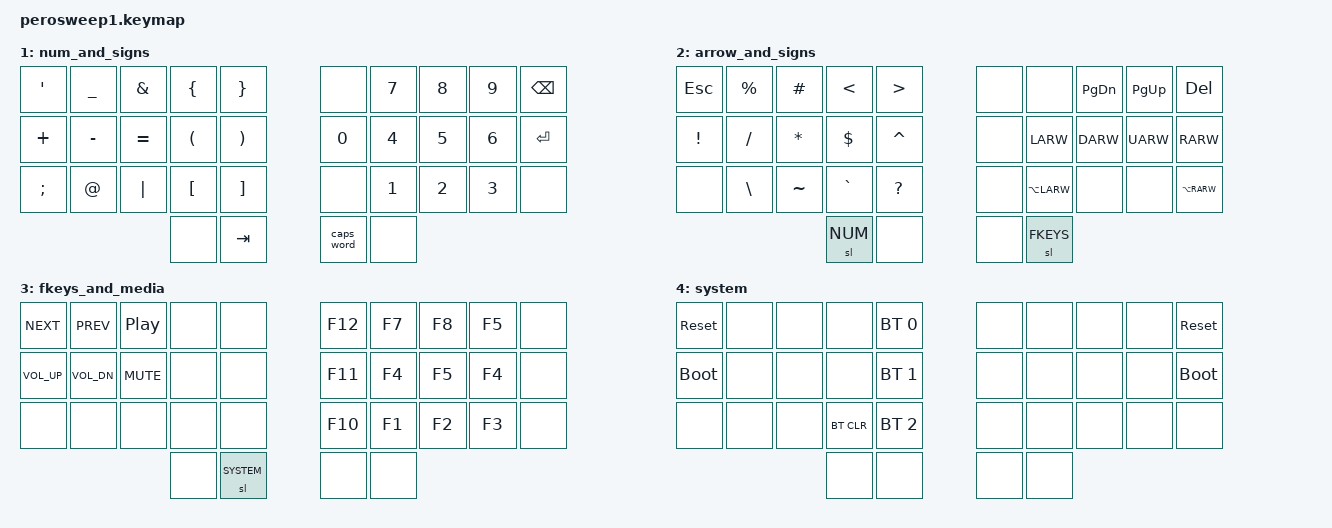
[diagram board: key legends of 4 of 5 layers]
#include <behaviors.dtsi>
#include <dt-bindings/zmk/keys.h>
#include <dt-bindings/zmk/bt.h>

#define ALPHA   0
#define NUM     1
#define ARROW   2
#define FKEYS   3 
#define SYSTEM  4 

// Home row mods macro
#define HRML(k1,k2,k3,k4) &mt LALT k1  &mt LGUI k2  &mt LSHIFT k3  &mt LCTRL k4
#define HRMR(k1,k2,k3,k4) &mt RCTRL k1  &mt RSHIFT k2  &mt RGUI k3  &mt RALT k4

&mt {
    // We use this for the MEH-key only.
    // Higher timeouts are required to prevent misfiring.
    tapping-term-ms = <230>;
    quick_tap_ms = <180>;
    global-quick-tap;
    flavor = "tap-preferred";
};

&sl {
    release-after-ms = <500>;
};

/ {
    behaviors {
        lm: home_row_left {
            compatible = "zmk,behavior-hold-tap";
            label = "home_row_left";
            #binding-cells = <2>;
            tapping-term-ms = <220>;
            quick_tap_ms = <180>;
            flavor = "balanced";
            bindings = <&kp>, <&kp>;
            hold-trigger-key-positions = <5 6 7 8 9 15 16 17 18 19 25 26 27 28 29 32 33>;
        };
        rm: home_row_right {
            compatible = "zmk,behavior-hold-tap";
            label = "home_row_right";
            #binding-cells = <2>;
            tapping-term-ms = <220>;
            quick_tap_ms = <180>;
            flavor = "balanced";
            bindings = <&kp>, <&kp>;
            hold-trigger-key-positions = <0 1 2 3 4 10 11 12 13 14 20 21 22 23 24 30 31>;
        };
    };

    keymap {
        compatible = "zmk,keymap";

        alpha {
        bindings = <

        //╭──────────┬──────────┬──────────┬──────────┬──────────╮   ╭──────────┬──────────┬──────────┬──────────┬──────────╮
        //│  Q       │  W       │  E       │  R       │  T       │   │  Y       │  U       │  I       │  O       │  P       │
            &kp Q      &kp W      &kp E      &kp R      &kp T          &kp Y      &kp U      &kp I      &kp O      &kp P
        //├──────────┼──────────┼──────────┼──────────┼──────────┤   ├──────────┼──────────┼──────────┼──────────┼──────────┤
        //│  A       │  S       │  D       │  F       │  G       │   │  H       │  J       │  K       │  L       │ ' "      │
            HRML(A,        S,         D,         F)     &kp G          &kp H      HRMR(J,        K,         L,        SQT)
        //├──────────┼──────────┼──────────┼──────────┼──────────┤   ├──────────┼──────────┼──────────┼──────────┼──────────┤
        //│  Z       │  X       │  C       │  V       │  B       │   │  N       │  M       │ , <      │ . >      │ / ?      │
            &kp Z      &kp X      &kp C      &kp V      &kp B          &kp N      &kp M      &kp COMMA  &kp DOT    &kp FSLH
        //╰──────────┴──────────┴──────────┼──────────┼──────────┤   ├──────────┼──────────┼──────────┴──────────┴──────────╯
         &sl ARROW  &mt LC(LS(LALT)) SPACE      &sl ARROW  &sl NUM
        >;
        };

        // TODO: We have to wait for `&sl` to time out for `&caps_word` to work.
        num_and_signs {
        bindings = <

        &kp SQT   &kp UNDER  &kp AMPS   &kp LBRC  &kp RBRC     &none   &kp N7  &kp N8  &kp N9  &kp BKSP
        &kp PLUS  &kp MINUS  &kp EQUAL  &kp LPAR  &kp RPAR     &kp N0  &kp N4  &kp N5  &kp N6  &kp ENTER
        &kp SEMI  &kp AT     &kp PIPE   &kp LBKT  &kp RBKT     &none   &kp N1  &kp N2  &kp N3  &none

                                            &none  &kp TAB     &caps_word  &none
        >;
        };

        arrow_and_signs {
        bindings = <

        &kp ESC   &kp PRCNT  &kp HASH   &kp LT     &kp GT       &none      &none         &kp PG_DN  &kp PG_UP  &kp DEL
        &kp EXCL  &kp SLASH  &kp ASTRK  &kp DLLR   &kp CARET    &none      &kp LARW      &kp DARW   &kp UARW   &kp RARW  
        &none     &kp BSLH   &kp TILDE  &kp GRAVE  &kp QMARK    &none      &kp LA(LARW)  &none      &none      &kp LA(RARW)    

                                              &sl NUM  &none    &none      &sl FKEYS
        >;
        };

        // The switch to the SYSTEM layer is put on the second thumb key on purpose
        // to prevent accidental system layer activations.
        fkeys_and_media {
        bindings = <

        &kp C_NEXT    &kp C_PREV    &kp C_PLAY_PAUSE  &none  &none      &kp F12  &kp F7  &kp F8  &kp F5  &none  
        &kp C_VOL_UP  &kp C_VOL_DN  &kp K_MUTE        &none  &none      &kp F11  &kp F4  &kp F5  &kp F4  &none  
        &none         &none         &none             &none  &none      &kp F10  &kp F1  &kp F2  &kp F3  &none  

                                                 &none  &sl SYSTEM      &none  &none
        >;
        };

        system {
        bindings = <

        &sys_reset   &none  &none  &none      &bt BT_SEL 0    &none  &none  &none  &none  &sys_reset
        &bootloader  &none  &none  &none      &bt BT_SEL 1    &none  &none  &none  &none  &bootloader
        &none        &none  &none  &bt BT_CLR &bt BT_SEL 2    &none  &none  &none  &none  &none

                                              &none  &none    &none  &none
        >;
        };
    };
};
